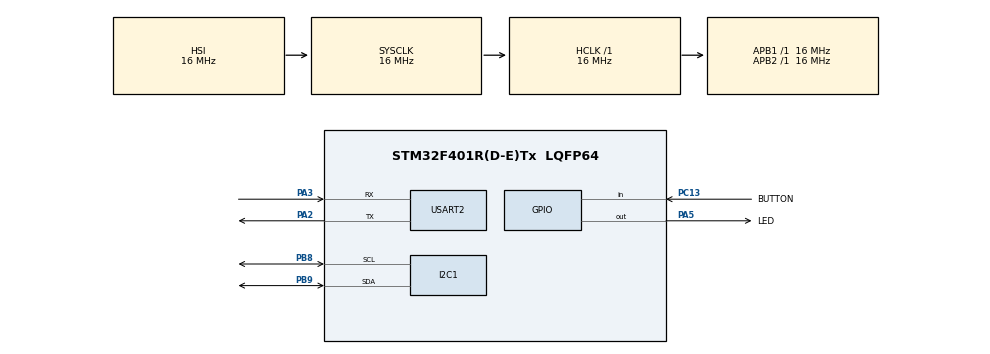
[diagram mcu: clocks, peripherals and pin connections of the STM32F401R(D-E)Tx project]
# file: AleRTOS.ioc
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FREERTOS.Queues01=alarmStateQueue,4,uint32_t,0,Dynamic,NULL,NULL;alarmEventQueue,8,uint32_t,0,Dynamic,NULL,NULL
FREERTOS.Tasks01=defaultTask,24,128,StartDefaultTask,Default,NULL,Dynamic,NULL,NULL;logicTask,24,256,StartTask02,Default,NULL,Dynamic,NULL,NULL;InputTask,24,256,StartTask03,Default,NULL,Dynamic,NULL,NULL
Mcu.Family=STM32F4
Mcu.Name=STM32F401R(D-E)Tx
Mcu.Package=LQFP64
NVIC.PriorityGroup=NVIC_PRIORITYGROUP_4
NVIC.TIM5_IRQn=true\:15\:0\:false\:false\:true\:false\:false\:true\:true
NVIC.TimeBase=TIM5_IRQn
NVIC.TimeBaseIP=TIM5
PA13.Mode=Serial_Wire
PA13.Signal=SYS_JTMS-SWDIO
PA14.Mode=Serial_Wire
PA14.Signal=SYS_JTCK-SWCLK
PA2.Mode=Asynchronous
PA2.Signal=USART2_TX
PA3.Mode=Asynchronous
PA3.Signal=USART2_RX
PA5.GPIO_Label=LED
PA5.Signal=GPIO_Output
PB8.Mode=I2C
PB8.Signal=I2C1_SCL
PB9.Mode=I2C
PB9.Signal=I2C1_SDA
PC13-ANTI_TAMP.GPIO_Label=BUTTON
PC13-ANTI_TAMP.Signal=GPIO_Input
ProjectManager.HeapSize=0x200
ProjectManager.StackSize=0x400
ProjectManager.TargetToolchain=STM32CubeIDE
RCC.AHBFreq_Value=16000000
RCC.APB1Freq_Value=16000000
RCC.APB2Freq_Value=16000000
RCC.CortexFreq_Value=16000000
RCC.HSE_VALUE=25000000
RCC.HSI_VALUE=16000000
RCC.LSE_VALUE=32768
RCC.SYSCLKFreq_VALUE=16000000
RCC.VCOOutputFreq_Value=192000000
USART2.VirtualMode=VM_ASYNC
VP_FREERTOS_VS_CMSIS_V2.Mode=CMSIS_V2
VP_SYS_VS_tim5.Mode=TIM5
board=custom

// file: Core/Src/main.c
/* USER CODE BEGIN Header */
/**
  ******************************************************************************
  * @file           : main.c
  * @brief          : Main program body
  ******************************************************************************
  * @attention
  *
  * Copyright (c) 2026 STMicroelectronics.
  * All rights reserved.
  *
  * This software is licensed under terms that can be found in the LICENSE file
  * in the root directory of this software component.
  * If no LICENSE file comes with this software, it is provided AS-IS.
  *
  ******************************************************************************
  */
/* USER CODE END Header */
#include "main.h"
#include "cmsis_os.h"

/* USER CODE BEGIN Includes */
#include "OutputTask.h"
#include "LogicTask.h"
#include "InputTask.h"
/* USER CODE END Includes */

I2C_HandleTypeDef hi2c1;

UART_HandleTypeDef huart2;

/* Definitions for defaultTask */
osThreadId_t defaultTaskHandle;
const osThreadAttr_t defaultTask_attributes = {
  .name = "defaultTask",
  .stack_size = 128 * 4,
  .priority = (osPriority_t) osPriorityNormal,
};
/* Definitions for logicTask */
osThreadId_t logicTaskHandle;
const osThreadAttr_t logicTask_attributes = {
  .name = "logicTask",
  .stack_size = 256 * 4,
  .priority = (osPriority_t) osPriorityNormal,
};
/* Definitions for InputTask */
osThreadId_t InputTaskHandle;
const osThreadAttr_t InputTask_attributes = {
  .name = "InputTask",
  .stack_size = 256 * 4,
  .priority = (osPriority_t) osPriorityNormal,
};
/* Definitions for alarmStateQueue */
osMessageQueueId_t alarmStateQueueHandle;
const osMessageQueueAttr_t alarmStateQueue_attributes = {
  .name = "alarmStateQueue"
};
/* Definitions for alarmEventQueue */
osMessageQueueId_t alarmEventQueueHandle;
const osMessageQueueAttr_t alarmEventQueue_attributes = {
  .name = "alarmEventQueue"
};

void SystemClock_Config(void);
static void MX_GPIO_Init(void);
static void MX_I2C1_Init(void);
static void MX_USART2_UART_Init(void);
void StartDefaultTask(void *argument);
void StartTask02(void *argument);
void StartTask03(void *argument);

int main(void)
{

  /* MCU Configuration--------------------------------------------------------*/

  /* Reset of all peripherals, Initializes the Flash interface and the Systick. */
  HAL_Init();

  /* Configure the system clock */
  SystemClock_Config();

  /* Initialize all configured peripherals */
  MX_GPIO_Init();
  MX_I2C1_Init();
  MX_USART2_UART_Init();

  /* Init scheduler */
  osKernelInitialize();

  /* Create the queue(s) */
  /* creation of alarmStateQueue */
  alarmStateQueueHandle = osMessageQueueNew (4, sizeof(uint32_t), &alarmStateQueue_attributes);

  /* creation of alarmEventQueue */
  alarmEventQueueHandle = osMessageQueueNew (8, sizeof(uint32_t), &alarmEventQueue_attributes);

  /* Create the thread(s) */
  /* creation of defaultTask */
  defaultTaskHandle = osThreadNew(StartDefaultTask, NULL, &defaultTask_attributes);

  /* creation of logicTask */
  logicTaskHandle = osThreadNew(StartTask02, NULL, &logicTask_attributes);

  /* creation of InputTask */
  InputTaskHandle = osThreadNew(StartTask03, NULL, &InputTask_attributes);

  /* Start scheduler */
  osKernelStart();

  /* We should never get here as control is now taken by the scheduler */

  /* Infinite loop */
  while (1)
  {

  }
}

void SystemClock_Config(void)
{
  RCC_OscInitTypeDef RCC_OscInitStruct = {0};
  RCC_ClkInitTypeDef RCC_ClkInitStruct = {0};

  /** Configure the main internal regulator output voltage
  */
  __HAL_RCC_PWR_CLK_ENABLE();
  __HAL_PWR_VOLTAGESCALING_CONFIG(PWR_REGULATOR_VOLTAGE_SCALE2);

  /** Initializes the RCC Oscillators according to the specified parameters
  * in the RCC_OscInitTypeDef structure.
  */
  RCC_OscInitStruct.OscillatorType = RCC_OSCILLATORTYPE_HSI;
  RCC_OscInitStruct.HSIState = RCC_HSI_ON;
  RCC_OscInitStruct.HSICalibrationValue = RCC_HSICALIBRATION_DEFAULT;
  RCC_OscInitStruct.PLL.PLLState = RCC_PLL_NONE;
  if (HAL_RCC_OscConfig(&RCC_OscInitStruct) != HAL_OK)
  {
    Error_Handler();
  }

  /** Initializes the CPU, AHB and APB buses clocks
  */
  RCC_ClkInitStruct.ClockType = RCC_CLOCKTYPE_HCLK|RCC_CLOCKTYPE_SYSCLK
                              |RCC_CLOCKTYPE_PCLK1|RCC_CLOCKTYPE_PCLK2;
  RCC_ClkInitStruct.SYSCLKSource = RCC_SYSCLKSOURCE_HSI;
  RCC_ClkInitStruct.AHBCLKDivider = RCC_SYSCLK_DIV1;
  RCC_ClkInitStruct.APB1CLKDivider = RCC_HCLK_DIV1;
  RCC_ClkInitStruct.APB2CLKDivider = RCC_HCLK_DIV1;

  if (HAL_RCC_ClockConfig(&RCC_ClkInitStruct, FLASH_LATENCY_0) != HAL_OK)
  {
    Error_Handler();
  }
}

static void MX_I2C1_Init(void)
{

  hi2c1.Instance = I2C1;
  hi2c1.Init.ClockSpeed = 100000;
  hi2c1.Init.DutyCycle = I2C_DUTYCYCLE_2;
  hi2c1.Init.OwnAddress1 = 0;
  hi2c1.Init.AddressingMode = I2C_ADDRESSINGMODE_7BIT;
  hi2c1.Init.DualAddressMode = I2C_DUALADDRESS_DISABLE;
  hi2c1.Init.OwnAddress2 = 0;
  hi2c1.Init.GeneralCallMode = I2C_GENERALCALL_DISABLE;
  hi2c1.Init.NoStretchMode = I2C_NOSTRETCH_DISABLE;
  if (HAL_I2C_Init(&hi2c1) != HAL_OK)
  {
    Error_Handler();
  }

}

static void MX_USART2_UART_Init(void)
{

  huart2.Instance = USART2;
  huart2.Init.BaudRate = 115200;
  huart2.Init.WordLength = UART_WORDLENGTH_8B;
  huart2.Init.StopBits = UART_STOPBITS_1;
  huart2.Init.Parity = UART_PARITY_NONE;
  huart2.Init.Mode = UART_MODE_TX_RX;
  huart2.Init.HwFlowCtl = UART_HWCONTROL_NONE;
  huart2.Init.OverSampling = UART_OVERSAMPLING_16;
  if (HAL_UART_Init(&huart2) != HAL_OK)
  {
    Error_Handler();
  }

}

static void MX_GPIO_Init(void)
{
  GPIO_InitTypeDef GPIO_InitStruct = {0};

  /* GPIO Ports Clock Enable */
  __HAL_RCC_GPIOC_CLK_ENABLE();
  __HAL_RCC_GPIOA_CLK_ENABLE();
  __HAL_RCC_GPIOB_CLK_ENABLE();

  /*Configure GPIO pin Output Level */
  HAL_GPIO_WritePin(LED_GPIO_Port, LED_Pin, GPIO_PIN_RESET);

  /*Configure GPIO pin : BUTTON_Pin */
  GPIO_InitStruct.Pin = BUTTON_Pin;
  GPIO_InitStruct.Mode = GPIO_MODE_INPUT;
  GPIO_InitStruct.Pull = GPIO_NOPULL;
  HAL_GPIO_Init(BUTTON_GPIO_Port, &GPIO_InitStruct);

  /*Configure GPIO pin : LED_Pin */
  GPIO_InitStruct.Pin = LED_Pin;
  GPIO_InitStruct.Mode = GPIO_MODE_OUTPUT_PP;
  GPIO_InitStruct.Pull = GPIO_NOPULL;
  GPIO_InitStruct.Speed = GPIO_SPEED_FREQ_LOW;
  HAL_GPIO_Init(LED_GPIO_Port, &GPIO_InitStruct);

}

void StartDefaultTask(void *argument)
{
  /* USER CODE BEGIN 5 */
  /* Infinite loop */
	OutputTask_Run(alarmStateQueueHandle);
  /* USER CODE END 5 */
}

void StartTask02(void *argument)
{
  /* USER CODE BEGIN StartTask02 */
  /* Infinite loop */
	LogicTask_Run(alarmEventQueueHandle,alarmStateQueueHandle);
  /* USER CODE END StartTask02 */
}

void StartTask03(void *argument)
{
  /* USER CODE BEGIN StartTask03 */
  /* Infinite loop */
	InputTask_Run(alarmEventQueueHandle);
  /* USER CODE END StartTask03 */
}

void HAL_TIM_PeriodElapsedCallback(TIM_HandleTypeDef *htim)
{
  if (htim->Instance == TIM5)
  {
    HAL_IncTick();
  }
}

void Error_Handler(void)
{
  __disable_irq();
  while (1)
  {
  }
}
